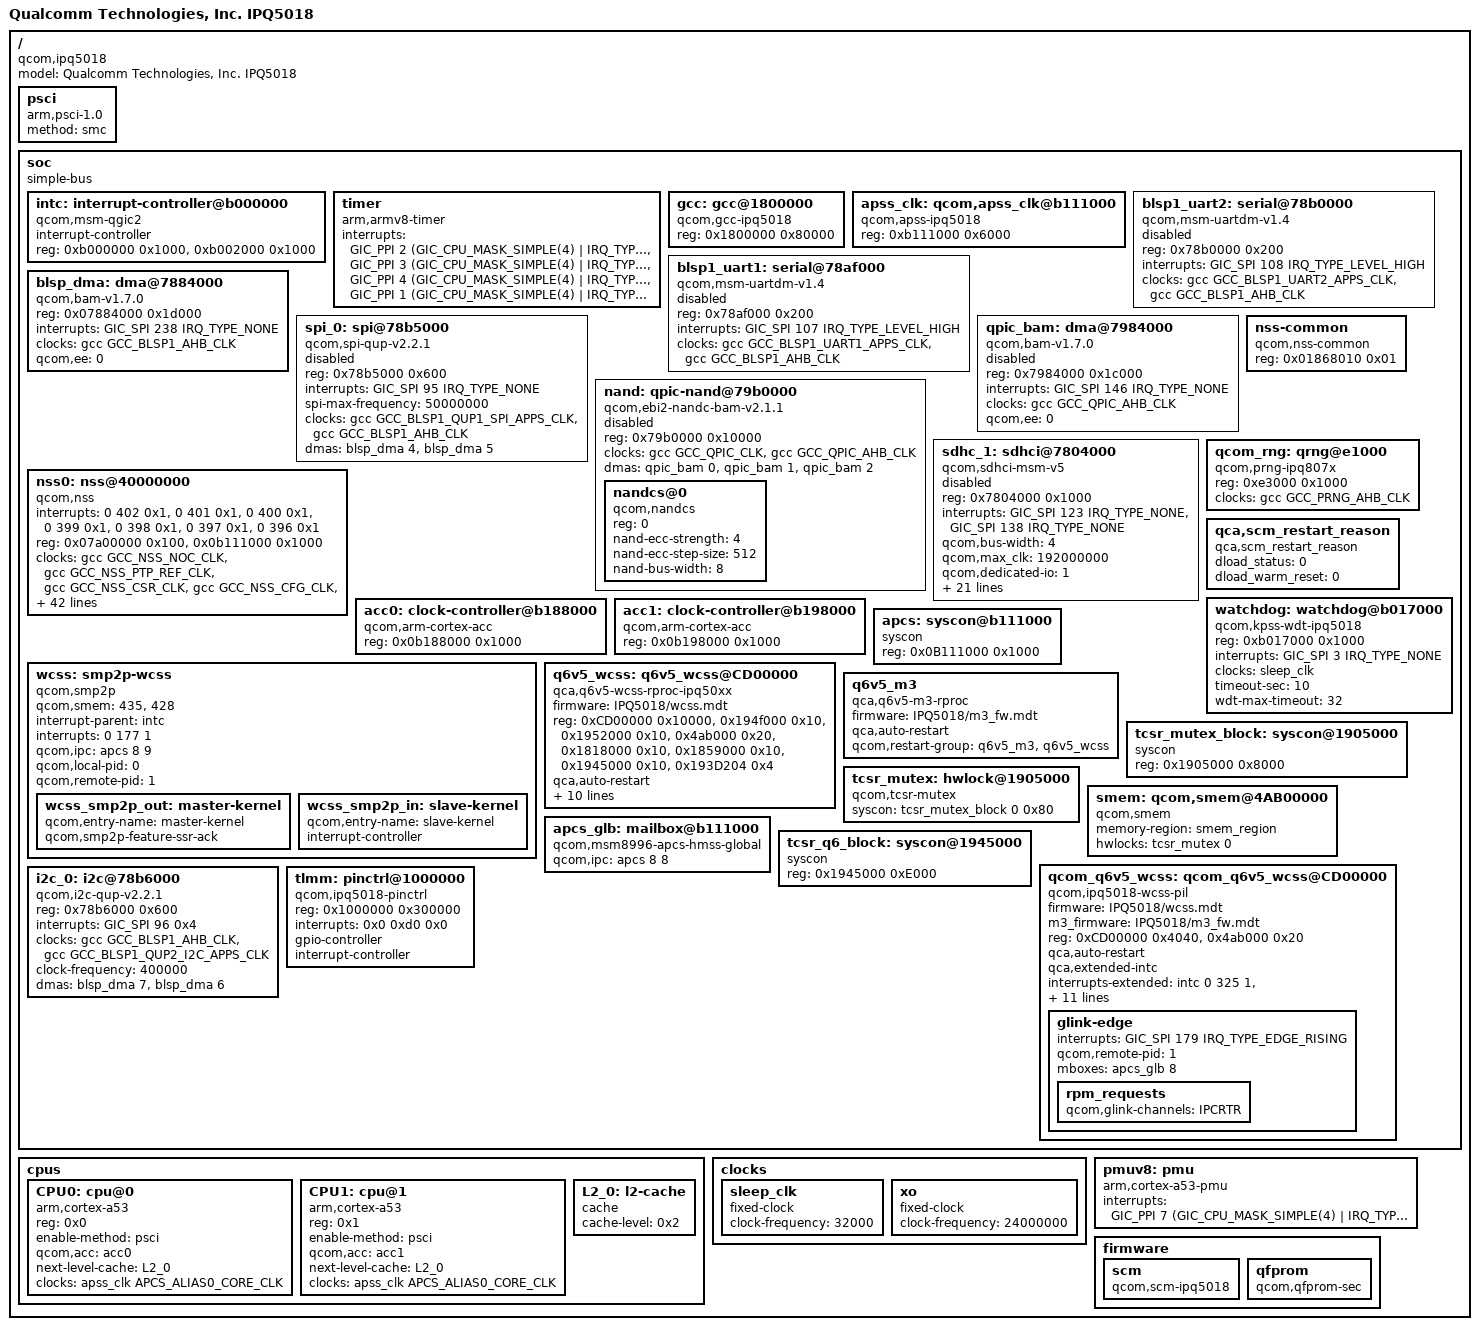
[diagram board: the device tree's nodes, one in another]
/*
 * Copyright (c) 2018-2020, The Linux Foundation. All rights reserved.
 *
 * Permission to use, copy, modify, and/or distribute this software for any
 * purpose with or without fee is hereby granted, provided that the above
 * copyright notice and this permission notice appear in all copies.
 *
 * THE SOFTWARE IS PROVIDED "AS IS" AND THE AUTHOR DISCLAIMS ALL WARRANTIES
 * WITH REGARD TO THIS SOFTWARE INCLUDING ALL IMPLIED WARRANTIES OF
 * MERCHANTABILITY AND FITNESS. IN NO EVENT SHALL THE AUTHOR BE LIABLE FOR
 * ANY SPECIAL, DIRECT, INDIRECT, OR CONSEQUENTIAL DAMAGES OR ANY DAMAGES
 * WHATSOEVER RESULTING FROM LOSS OF USE, DATA OR PROFITS, WHETHER IN AN
 * ACTION OF CONTRACT, NEGLIGENCE OR OTHER TORTIOUS ACTION, ARISING OUT OF
 * OR IN CONNECTION WITH THE USE OR PERFORMANCE OF THIS SOFTWARE.
 */

#include <dt-bindings/interrupt-controller/arm-gic.h>
#include <dt-bindings/clock/qcom,gcc-ipq5018.h>
#include <dt-bindings/reset/qcom,gcc-ipq5018.h>
#include <dt-bindings/clock/qca,apss-ipq5018.h>
#include "qcom-ipq5018-memory.dtsi"

/ {
	model = "Qualcomm Technologies, Inc. IPQ5018";
	compatible = "qcom,ipq5018";

	psci {
		compatible = "arm,psci-1.0";
		method = "smc";
		status = "ok";
	};

	soc: soc {
		#address-cells = <0x1>;
		#size-cells = <0x1>;
		ranges = <0 0 0 0xffffffff>;
		compatible = "simple-bus";

		intc: interrupt-controller@b000000 {
			compatible = "qcom,msm-qgic2";
			interrupt-controller;
			#interrupt-cells = <0x3>;
			reg = <0xb000000 0x1000>, <0xb002000 0x1000>;
		};

		timer {
			compatible = "arm,armv8-timer";
			interrupts = <GIC_PPI 2 (GIC_CPU_MASK_SIMPLE(4) | IRQ_TYPE_LEVEL_LOW)>,
					<GIC_PPI 3 (GIC_CPU_MASK_SIMPLE(4) | IRQ_TYPE_LEVEL_LOW)>,
					<GIC_PPI 4 (GIC_CPU_MASK_SIMPLE(4) | IRQ_TYPE_LEVEL_LOW)>,
					<GIC_PPI 1 (GIC_CPU_MASK_SIMPLE(4) | IRQ_TYPE_LEVEL_LOW)>;
		};

		gcc: gcc@1800000 {
			compatible = "qcom,gcc-ipq5018";
			reg = <0x1800000 0x80000>;
			#clock-cells = <0x1>;
			#reset-cells = <0x1>;
		};

		apss_clk: qcom,apss_clk@b111000 {
			compatible = "qcom,apss-ipq5018";
			reg = <0xb111000 0x6000>;
			#clock-cells = <0x1>;
			#reset-cells = <1>;
		};

		blsp1_uart2: serial@78b0000 {
			compatible = "qcom,msm-uartdm-v1.4", "qcom,msm-uartdm";
			reg = <0x78b0000 0x200>;
			interrupts = <GIC_SPI 108 IRQ_TYPE_LEVEL_HIGH>;
			clocks = <&gcc GCC_BLSP1_UART2_APPS_CLK>,
					<&gcc GCC_BLSP1_AHB_CLK>;
			clock-names = "core", "iface";
			status = "disabled";
		};

		blsp1_uart1: serial@78af000 {
			compatible = "qcom,msm-uartdm-v1.4", "qcom,msm-uartdm";
			reg = <0x78af000 0x200>;
			interrupts = <GIC_SPI 107 IRQ_TYPE_LEVEL_HIGH>;
			clocks = <&gcc GCC_BLSP1_UART1_APPS_CLK>,
					<&gcc GCC_BLSP1_AHB_CLK>;
			clock-names = "core", "iface";
			status = "disabled";
		};

		blsp_dma: dma@7884000 {
			compatible = "qcom,bam-v1.7.0";
			reg = <0x07884000 0x1d000>;
			interrupts = <GIC_SPI 238 IRQ_TYPE_NONE>;
			clocks = <&gcc GCC_BLSP1_AHB_CLK>;
			clock-names = "bam_clk";
			#dma-cells = <1>;
			qcom,ee = <0>;
		};

		spi_0: spi@78b5000 { /* BLSP1 QUP0 */
			compatible = "qcom,spi-qup-v2.2.1";
			#address-cells = <1>;
			#size-cells = <0>;
			reg = <0x78b5000 0x600>;
			interrupts = <GIC_SPI 95 IRQ_TYPE_NONE>;
			spi-max-frequency = <50000000>;
			clocks = <&gcc GCC_BLSP1_QUP1_SPI_APPS_CLK>,
				<&gcc GCC_BLSP1_AHB_CLK>;
			clock-names = "core", "iface";
			dmas = <&blsp_dma 4>, <&blsp_dma 5>;
			dma-names = "tx", "rx";
			status = "disabled";
		};

		qpic_bam: dma@7984000{
			compatible = "qcom,bam-v1.7.0";
			reg = <0x7984000 0x1c000>;
			interrupts = <GIC_SPI 146 IRQ_TYPE_NONE>;
			clocks = <&gcc GCC_QPIC_AHB_CLK>;
			clock-names = "bam_clk";
			#dma-cells = <1>;
			qcom,ee = <0>;
			status = "disabled";
		};

		nand: qpic-nand@79b0000 {
			compatible = "qcom,ebi2-nandc-bam-v2.1.1";
			reg = <0x79b0000 0x10000>;
			#address-cells = <1>;
			#size-cells = <0>;
			clocks = <&gcc GCC_QPIC_CLK>,
				<&gcc GCC_QPIC_AHB_CLK>;
			clock-names = "core", "aon";

			dmas = <&qpic_bam 0>,
				<&qpic_bam 1>,
				<&qpic_bam 2>;
			dma-names = "tx", "rx", "cmd";
			status = "disabled";

			nandcs@0 {
				compatible = "qcom,nandcs";
				reg = <0>;
				#address-cells = <1>;
				#size-cells = <1>;

				nand-ecc-strength = <4>;
				nand-ecc-step-size = <512>;
				nand-bus-width = <8>;
			};
		};

		sdhc_1: sdhci@7804000 {
			compatible = "qcom,sdhci-msm-v5";
			reg = <0x7804000 0x1000>;
			reg-names = "hc_mem";

			interrupts = <GIC_SPI 123 IRQ_TYPE_NONE>,
					<GIC_SPI 138 IRQ_TYPE_NONE>;
			interrupt-names = "hc_irq", "pwr_irq";

			qcom,bus-width = <4>;
			qcom,max_clk = <192000000>;

			qcom,dedicated-io = <1>;

			/* device core power supply */
			qcom,vdd-voltage-level = <2900000 2900000>;
			qcom,vdd-current-level = <200 570000>;

			/* device communication power supply */
			qcom,vdd-io-lpm-sup;
			qcom,vdd-io-voltage-level = <1800000 1800000>;
			qcom,vdd-io-current-level = <200 325000>;
			qcom,vdd-io-always-on;

			qcom,cpu-dma-latency-us = <701>;
			qcom,msm-bus,name = "sdhc1";
			qcom,msm-bus,num-cases = <9>;
			qcom,msm-bus,num-paths = <1>;
			qcom,msm-bus,vectors-KBps = <78 512 0 0>, /* No vote */
				<78 512 1046 3200>,    /* 400 KB/s*/
				<78 512 52286 160000>, /* 20 MB/s */
				<78 512 65360 200000>, /* 25 MB/s */
				<78 512 130718 400000>, /* 50 MB/s */
				<78 512 261438 800000>, /* 100 MB/s */
				<78 512 261438 800000>, /* 200 MB/s */
				<78 512 261438 800000>, /* 400 MB/s */
				<78 512 1338562 4096000>; /* Max. bandwidth */
			qcom,bus-bw-vectors-bps = <0 400000 20000000 25000000 \
						50000000 100000000 200000000 \
						400000000 4294967295>;

			clocks = <&gcc GCC_SDCC1_AHB_CLK>,
				 <&gcc GCC_SDCC1_APPS_CLK>;
			clock-names = "iface_clk", "core_clk";
			qcom,large-address-bus;
			qcom,disable-aggressive-pm;
			status = "disabled";
		};

		nss-common {
			compatible = "qcom,nss-common";
			reg = <0x01868010 0x01>;
			reg-names = "nss-misc-reset";
		};

		nss0: nss@40000000 {
			compatible = "qcom,nss";
			interrupts = <0 402 0x1>, <0 401 0x1>, <0 400 0x1>,
				     <0 399 0x1>, <0 398 0x1>, <0 397 0x1>,
				     <0 396 0x1>;
			reg = <0x07a00000 0x100>, <0x0b111000 0x1000>;
			reg-names = "nphys", "qgic-phys";
			clocks = <&gcc GCC_NSS_NOC_CLK>,
				 <&gcc GCC_NSS_PTP_REF_CLK>,
				 <&gcc GCC_NSS_CSR_CLK>, <&gcc GCC_NSS_CFG_CLK>,
				 <&gcc GCC_NSSNOC_QOSGEN_REF_CLK>,
				 <&gcc GCC_NSSNOC_SNOC_CLK>,
				 <&gcc GCC_NSSNOC_TIMEOUT_REF_CLK>,
				 <&gcc GCC_MEM_NOC_UBI32_CLK>,
				 <&gcc GCC_NSS_CE_AXI_CLK>,
				 <&gcc GCC_NSS_CE_APB_CLK>,
				 <&gcc GCC_NSSNOC_CE_AXI_CLK>,
				 <&gcc GCC_NSSNOC_CE_APB_CLK>,
				 <&gcc GCC_NSSNOC_UBI0_AHB_CLK>,
				 <&gcc GCC_UBI0_CORE_CLK>,
				 <&gcc GCC_UBI0_AHB_CLK>,
				 <&gcc GCC_UBI0_AXI_CLK>,
				 <&gcc GCC_UBI0_NC_AXI_CLK>,
				 <&gcc GCC_SNOC_NSSNOC_CLK>;
			clock-names = "nss-noc-clk", "nss-ptp-ref-clk",
				      "nss-csr-clk", "nss-cfg-clk",
				      "nss-nssnoc-qosgen-ref-clk",
				      "nss-nssnoc-snoc-clk",
				      "nss-nssnoc-timeout-ref-clk",
				      "nss-mem-noc-ubi32-clk",
				      "nss-ce-axi-clk", "nss-ce-apb-clk",
				      "nss-nssnoc-ce-axi-clk",
				      "nss-nssnoc-ce-apb-clk",
				      "nss-nssnoc-ahb-clk",
				      "nss-core-clk", "nss-ahb-clk",
				      "nss-axi-clk", "nss-nc-axi-clk",
				      "nss-snoc-nssnoc-clk";
			qcom,id = <0>;
			qcom,num-queue = <4>;
			qcom,num-irq = <7>;
			qcom,num-pri = <4>;
			qcom,load-addr = <0x40000000>;
			qcom,low-frequency = <850000000>;
			qcom,mid-frequency = <850000000>;
			qcom,max-frequency = <1000000000>;
			qcom,ipv4-enabled;
			qcom,ipv4-reasm-enabled;
			qcom,ipv6-enabled;
			qcom,ipv6-reasm-enabled;
			qcom,wlanredirect-enabled;
			qcom,tun6rd-enabled;
			qcom,l2tpv2-enabled;
			qcom,gre-enabled;
			qcom,gre-redir-enabled;
			qcom,gre-redir-mark-enabled;
			qcom,map-t-enabled;
			qcom,portid-enabled;
			qcom,pppoe-enabled;
			qcom,pptp-enabled;
			qcom,tunipip6-enabled;
			qcom,shaping-enabled;
			qcom,wlan-dataplane-offload-enabled;
			qcom,pvxlan-enabled;
			qcom,clmap-enabled;
			qcom,vxlan-enabled;
			qcom,match-enabled;
		};

		acc0:clock-controller@b188000 {
			compatible = "qcom,arm-cortex-acc";
			reg = <0x0b188000 0x1000>;
		};

		acc1:clock-controller@b198000 {
			compatible = "qcom,arm-cortex-acc";
			reg = <0x0b198000 0x1000>;
		};

		qcom_rng: qrng@e1000 {
			compatible = "qcom,prng-ipq807x";
			reg = <0xe3000 0x1000>;
			clocks = <&gcc GCC_PRNG_AHB_CLK>;
			clock-names = "core";
			status = "ok";
		};

		qca,scm_restart_reason {
			compatible = "qca,scm_restart_reason";
			dload_status = <0>;
			dload_warm_reset = <0>;
		};

		watchdog: watchdog@b017000 {
			compatible = "qcom,kpss-wdt-ipq5018";
			reg = <0xb017000 0x1000>;
			reg-names = "kpss_wdt";
			interrupt-names = "bark_irq";
			interrupts = <GIC_SPI 3 IRQ_TYPE_NONE>;
			clocks = <&sleep_clk>;
			timeout-sec = <10>;
			wdt-max-timeout = <32>;
		};

		apcs: syscon@b111000 {
			compatible = "syscon";
			reg = <0x0B111000 0x1000>;
		};

		wcss: smp2p-wcss {
			compatible = "qcom,smp2p";
			qcom,smem = <435>, <428>;

			interrupt-parent = <&intc>;
			interrupts = <0 177 1>;

			qcom,ipc = <&apcs 8 9>;

			qcom,local-pid = <0>;
			qcom,remote-pid = <1>;

			wcss_smp2p_out: master-kernel {
				qcom,entry-name = "master-kernel";
				qcom,smp2p-feature-ssr-ack;
				#qcom,smem-state-cells = <1>;
			};

			wcss_smp2p_in: slave-kernel {
				qcom,entry-name = "slave-kernel";
				interrupt-controller;
				#interrupt-cells = <2>;
			};
		};

		q6v5_wcss: q6v5_wcss@CD00000 {
			compatible = "qca,q6v5-wcss-rproc-ipq50xx";
			firmware = "IPQ5018/wcss.mdt";
			reg = <0xCD00000 0x10000>,
				<0x194f000 0x10>,
				<0x1952000 0x10>,
				<0x4ab000 0x20>,
				<0x1818000 0x10>,
				<0x1859000 0x10>,
				<0x1945000 0x10>,
				<0x193D204 0x4>;
			reg-names = "wcss-base",
					"tcsr-q6-base",
					"tcsr-base",
					"mpm-base",
					"gcc-wcss-bcr-base",
					"gcc-wcss-misc-base",
					"tcsr-global",
					"tcsr-q6-boot-trig";
			qca,auto-restart;
			qca,extended-intc;
			qca,dump-q6-reg;
			qca,emulation;
			memory-region = <&q6_region>, <&q6_etr_region>;
			interrupts-extended = <&intc 0 325 1>,
					<&wcss_smp2p_in 0 0>,
					<&wcss_smp2p_in 1 0>,
					<&wcss_smp2p_in 3 0>;
			interrupt-names = "wdog",
					"qcom,gpio-err-fatal",
					"qcom,gpio-err-ready",
					"qcom,gpio-stop-ack";
			qcom,smem-states = <&wcss_smp2p_out 0>,
					<&wcss_smp2p_out 1>;
			qcom,smem-state-names = "shutdown",
						"stop";
		};

		q6v5_m3: q6v5_m3 {
			compatible = "qca,q6v5-m3-rproc";
			firmware = "IPQ5018/m3_fw.mdt";
			qca,auto-restart;
			qcom,restart-group = <&q6v5_m3 &q6v5_wcss>;
		};

		tcsr_mutex_block: syscon@1905000 {
			compatible = "syscon";
			reg = <0x1905000 0x8000>;
		};

		tcsr_mutex: hwlock@1905000 {
			compatible = "qcom,tcsr-mutex";
			syscon = <&tcsr_mutex_block 0 0x80>;
			#hwlock-cells = <1>;
		};

		smem: qcom,smem@4AB00000 {
			compatible = "qcom,smem";
			memory-region = <&smem_region>;
			hwlocks = <&tcsr_mutex 0>;
		};

		apcs_glb: mailbox@b111000 {
			compatible = "qcom,msm8996-apcs-hmss-global";
			qcom,ipc = <&apcs 8 8>;

			#mbox-cells = <1>;
		};

		tcsr_q6_block: syscon@1945000 {
			compatible = "syscon";
			reg = <0x1945000 0xE000>;
		};

		qcom_q6v5_wcss: qcom_q6v5_wcss@CD00000 {
			compatible = "qcom,ipq5018-wcss-pil";
			firmware = "IPQ5018/wcss.mdt";
			m3_firmware = "IPQ5018/m3_fw.mdt";
			reg = <0xCD00000 0x4040>,
				<0x4ab000 0x20>;
			reg-names = "qdsp6",
				"rmb";
			qca,auto-restart;
			qca,extended-intc;
			interrupts-extended = <&intc 0 325 1>,
					<&wcss_smp2p_in 0 0>,
					<&wcss_smp2p_in 1 0>,
					<&wcss_smp2p_in 2 0>,
					<&wcss_smp2p_in 3 0>;
			interrupt-names = "wdog",
					"fatal",
					"ready",
					"handover",
					"stop-ack";

			resets = <&gcc GCC_WCSSAON_RESET>,
				<&gcc GCC_WCSS_BCR>,
				<&gcc GCC_WCSS_Q6_BCR>;

			reset-names = "wcss_aon_reset",
				"wcss_reset",
				"wcss_q6_reset";

			qcom,halt-regs = <&tcsr_q6_block 0xA000 0xD000 0x0>;

			qcom,smem-states = <&wcss_smp2p_out 0>,
					<&wcss_smp2p_out 1>;
			qcom,smem-state-names = "shutdown",
						"stop";

			memory-region = <&q6_region>;

			qcom,q6v6;

			glink-edge {
				interrupts = <GIC_SPI 179 IRQ_TYPE_EDGE_RISING>;
				qcom,remote-pid = <1>;
				mboxes = <&apcs_glb 8>;

				rpm_requests {
					qcom,glink-channels = "IPCRTR";
				};
			};
		};

		i2c_0: i2c@78b6000 {
			compatible = "qcom,i2c-qup-v2.2.1";
			#address-cells = <1>;
			#size-cells = <0>;
			reg = <0x78b6000 0x600>;
			interrupts = <GIC_SPI 96 0x4>;
			clocks = <&gcc GCC_BLSP1_AHB_CLK>,
				<&gcc GCC_BLSP1_QUP2_I2C_APPS_CLK>;
			clock-names = "iface", "core";
			clock-frequency  = <400000>;
			dmas = <&blsp_dma 7>, <&blsp_dma 6>;
			dma-names = "rx", "tx";
		};

		tlmm: pinctrl@1000000 {
			compatible = "qcom,ipq5018-pinctrl";
			reg = <0x1000000 0x300000>;
			interrupts = <0x0 0xd0 0x0>;
			gpio-controller;
			#gpio-cells = <0x2>;
			interrupt-controller;
			#interrupt-cells = <0x2>;
		};
	};

	cpus {
		#address-cells = <0x1>;
		#size-cells = <0x0>;

		CPU0: cpu@0 {
			device_type = "cpu";
			compatible = "arm,cortex-a53";
			reg = <0x0>;
			enable-method = "psci";
			qcom,acc = <&acc0>;
			next-level-cache = <&L2_0>;
			clocks = <&apss_clk APCS_ALIAS0_CORE_CLK>;
			clock-names = "cpu";
		};

		CPU1: cpu@1 {
			device_type = "cpu";
			compatible = "arm,cortex-a53";
			reg = <0x1>;
			enable-method = "psci";
			qcom,acc = <&acc1>;
			next-level-cache = <&L2_0>;
			clocks = <&apss_clk APCS_ALIAS0_CORE_CLK>;
			clock-names = "cpu";
		};

		L2_0: l2-cache {
			compatible = "cache";
			cache-level = <0x2>;
		};
	};

	clocks {
		sleep_clk: sleep_clk {
			compatible = "fixed-clock";
			clock-frequency = <32000>;
			#clock-cells = <0>;
		};

		xo: xo {
			compatible = "fixed-clock";
			clock-frequency = <24000000>;
			#clock-cells = <0>;
		};
	};

	pmuv8: pmu {
		compatible = "arm,cortex-a53-pmu";
		interrupts = <GIC_PPI 7 (GIC_CPU_MASK_SIMPLE(4) |
					 IRQ_TYPE_LEVEL_HIGH)>;
	};

	firmware {
		scm {
			compatible = "qcom,scm-ipq5018";
		};
		qfprom {
			compatible = "qcom,qfprom-sec";
		};
	};

};
